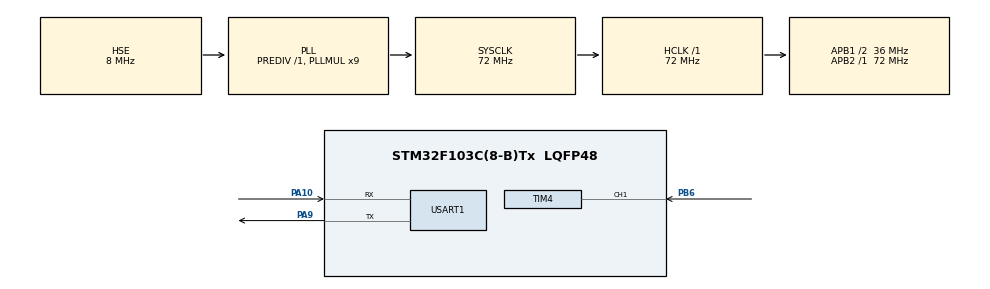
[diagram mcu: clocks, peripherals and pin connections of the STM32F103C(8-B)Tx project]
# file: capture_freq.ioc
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Mcu.Family=STM32F1
Mcu.Name=STM32F103C(8-B)Tx
Mcu.Package=LQFP48
NVIC.PriorityGroup=NVIC_PRIORITYGROUP_4
NVIC.TIM4_IRQn=true\:0\:0\:false\:false\:true\:true\:true
PA10.Mode=Asynchronous
PA10.Signal=USART1_RX
PA13.Mode=Serial_Wire
PA13.Signal=SYS_JTMS-SWDIO
PA14.Mode=Serial_Wire
PA14.Signal=SYS_JTCK-SWCLK
PA9.Mode=Asynchronous
PA9.Signal=USART1_TX
PB6.Signal=S_TIM4_CH1
PD0-OSC_IN.Mode=HSE-External-Oscillator
PD0-OSC_IN.Signal=RCC_OSC_IN
PD1-OSC_OUT.Mode=HSE-External-Oscillator
PD1-OSC_OUT.Signal=RCC_OSC_OUT
ProjectManager.HeapSize=0x200
ProjectManager.StackSize=0x400
ProjectManager.TargetToolchain=TrueSTUDIO
RCC.AHBFreq_Value=72000000
RCC.APB1CLKDivider=RCC_HCLK_DIV2
RCC.APB1Freq_Value=36000000
RCC.APB1TimFreq_Value=72000000
RCC.APB2Freq_Value=72000000
RCC.APB2TimFreq_Value=72000000
RCC.HCLKFreq_Value=72000000
RCC.PLLMUL=RCC_PLL_MUL9
RCC.PLLSourceVirtual=RCC_PLLSOURCE_HSE
RCC.RCC_MCOSource=RCC_MCO1SOURCE_HSE
RCC.SYSCLKFreq_VALUE=72000000
RCC.SYSCLKSource=RCC_SYSCLKSOURCE_PLLCLK
RCC.USBFreq_Value=72000000
SH.S_TIM4_CH1.0=TIM4_CH1,Input_Capture1_from_TI1
TIM3.Period=65535
TIM4.Channel-Input_Capture1_from_TI1=TIM_CHANNEL_1
TIM4.Period=65535
TIM4.Prescaler=71
TIM4.TIM_MasterOutputTrigger=TIM_TRGO_UPDATE
USART1.VirtualMode=VM_ASYNC
VP_TIM3_VS_ClockSourceITR.Mode=TriggerSource_ITR3
VP_TIM3_VS_ControllerModeClock.Mode=Clock Mode
board=custom

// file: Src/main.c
/* USER CODE BEGIN Header */
/**
  ******************************************************************************
  * @file           : main.c
  * @brief          : Main program body
  ******************************************************************************
  * @attention
  *
  * <h2><center>&copy; Copyright (c) 2019 STMicroelectronics.
  * All rights reserved.</center></h2>
  *
  * This software component is licensed by ST under BSD 3-Clause license,
  * the "License"; You may not use this file except in compliance with the
  * License. You may obtain a copy of the License at:
  *                        opensource.org/licenses/BSD-3-Clause
  *
  ******************************************************************************
  */
/* USER CODE END Header */

#include "main.h"

/* USER CODE BEGIN Includes */
#include "string.h"
/* USER CODE END Includes */

TIM_HandleTypeDef htim3;
TIM_HandleTypeDef htim4;

UART_HandleTypeDef huart1;

/* USER CODE BEGIN PV */
volatile uint8_t count = 0;
/* USER CODE END PV */

void SystemClock_Config(void);
static void MX_GPIO_Init(void);
static void MX_TIM4_Init(void);
static void MX_USART1_UART_Init(void);
static void MX_TIM3_Init(void);

/* USER CODE BEGIN 0 */

void HAL_TIM_IC_CaptureCallback(TIM_HandleTypeDef *htim)
{
	if(htim == &htim4)
	{
		if(htim->Channel == HAL_TIM_ACTIVE_CHANNEL_1)
		{
			count++;

			if(count == 1)
			{
				__HAL_TIM_SET_COUNTER(&htim4, 0x0000);
				__HAL_TIM_SET_COUNTER(&htim3, 0x0000);
			}

			else if(count == 2)
			{
				HAL_TIM_IC_Stop_IT(&htim4, TIM_CHANNEL_1);

				count = 0;

				uint16_t count_main = HAL_TIM_ReadCapturedValue(&htim4, TIM_CHANNEL_1);
				uint16_t count_secondary = __HAL_TIM_GET_COUNTER(&htim3);
				uint16_t arr = __HAL_TIM_GET_AUTORELOAD(&htim3);
				uint32_t res = count_main + (count_secondary * arr) + count_secondary;

				float freq = 1 / (res / 1000000.0);

				char str[96] = {0,};
				//snprintf(str, 96, "Capture Freq: %.3f Hz | res: %lu | cm: %d | cs: %d\n", (float)freq, res, count_main, count_secondary);
				snprintf(str, 96, "Capture Freq: %.3f Hz\n", (float)freq);
				HAL_UART_Transmit(&huart1, (uint8_t*)str, strlen(str), 1000);

				HAL_TIM_IC_Start_IT(&htim4, TIM_CHANNEL_1);
			}
		}
	}
}

/* USER CODE END 0 */

int main(void)
{

  /* MCU Configuration--------------------------------------------------------*/

  /* Reset of all peripherals, Initializes the Flash interface and the Systick. */
  HAL_Init();

  /* Configure the system clock */
  SystemClock_Config();

  /* Initialize all configured peripherals */
  MX_GPIO_Init();
  MX_TIM4_Init();
  MX_USART1_UART_Init();
  MX_TIM3_Init();
  /* USER CODE BEGIN 2 */

  HAL_TIM_IC_Start_IT(&htim4, TIM_CHANNEL_1);
  HAL_TIM_Base_Start(&htim3);

  /* USER CODE END 2 */

  /* Infinite loop */
  while (1)
  {

  }
}

void SystemClock_Config(void)
{
  RCC_OscInitTypeDef RCC_OscInitStruct = {0};
  RCC_ClkInitTypeDef RCC_ClkInitStruct = {0};

  /** Initializes the CPU, AHB and APB busses clocks
  */
  RCC_OscInitStruct.OscillatorType = RCC_OSCILLATORTYPE_HSE;
  RCC_OscInitStruct.HSEState = RCC_HSE_ON;
  RCC_OscInitStruct.HSEPredivValue = RCC_HSE_PREDIV_DIV1;
  RCC_OscInitStruct.HSIState = RCC_HSI_ON;
  RCC_OscInitStruct.PLL.PLLState = RCC_PLL_ON;
  RCC_OscInitStruct.PLL.PLLSource = RCC_PLLSOURCE_HSE;
  RCC_OscInitStruct.PLL.PLLMUL = RCC_PLL_MUL9;
  if (HAL_RCC_OscConfig(&RCC_OscInitStruct) != HAL_OK)
  {
    Error_Handler();
  }
  /** Initializes the CPU, AHB and APB busses clocks
  */
  RCC_ClkInitStruct.ClockType = RCC_CLOCKTYPE_HCLK|RCC_CLOCKTYPE_SYSCLK
                              |RCC_CLOCKTYPE_PCLK1|RCC_CLOCKTYPE_PCLK2;
  RCC_ClkInitStruct.SYSCLKSource = RCC_SYSCLKSOURCE_PLLCLK;
  RCC_ClkInitStruct.AHBCLKDivider = RCC_SYSCLK_DIV1;
  RCC_ClkInitStruct.APB1CLKDivider = RCC_HCLK_DIV2;
  RCC_ClkInitStruct.APB2CLKDivider = RCC_HCLK_DIV1;

  if (HAL_RCC_ClockConfig(&RCC_ClkInitStruct, FLASH_LATENCY_2) != HAL_OK)
  {
    Error_Handler();
  }
}

static void MX_TIM3_Init(void)
{

  TIM_SlaveConfigTypeDef sSlaveConfig = {0};
  TIM_MasterConfigTypeDef sMasterConfig = {0};

  htim3.Instance = TIM3;
  htim3.Init.Prescaler = 0;
  htim3.Init.CounterMode = TIM_COUNTERMODE_UP;
  htim3.Init.Period = 65535;
  htim3.Init.ClockDivision = TIM_CLOCKDIVISION_DIV1;
  htim3.Init.AutoReloadPreload = TIM_AUTORELOAD_PRELOAD_DISABLE;
  if (HAL_TIM_Base_Init(&htim3) != HAL_OK)
  {
    Error_Handler();
  }
  sSlaveConfig.SlaveMode = TIM_SLAVEMODE_EXTERNAL1;
  sSlaveConfig.InputTrigger = TIM_TS_ITR3;
  if (HAL_TIM_SlaveConfigSynchronization(&htim3, &sSlaveConfig) != HAL_OK)
  {
    Error_Handler();
  }
  sMasterConfig.MasterOutputTrigger = TIM_TRGO_RESET;
  sMasterConfig.MasterSlaveMode = TIM_MASTERSLAVEMODE_DISABLE;
  if (HAL_TIMEx_MasterConfigSynchronization(&htim3, &sMasterConfig) != HAL_OK)
  {
    Error_Handler();
  }

}

static void MX_TIM4_Init(void)
{

  TIM_MasterConfigTypeDef sMasterConfig = {0};
  TIM_IC_InitTypeDef sConfigIC = {0};

  htim4.Instance = TIM4;
  htim4.Init.Prescaler = 71;
  htim4.Init.CounterMode = TIM_COUNTERMODE_UP;
  htim4.Init.Period = 65535;
  htim4.Init.ClockDivision = TIM_CLOCKDIVISION_DIV1;
  htim4.Init.AutoReloadPreload = TIM_AUTORELOAD_PRELOAD_DISABLE;
  if (HAL_TIM_IC_Init(&htim4) != HAL_OK)
  {
    Error_Handler();
  }
  sMasterConfig.MasterOutputTrigger = TIM_TRGO_UPDATE;
  sMasterConfig.MasterSlaveMode = TIM_MASTERSLAVEMODE_DISABLE;
  if (HAL_TIMEx_MasterConfigSynchronization(&htim4, &sMasterConfig) != HAL_OK)
  {
    Error_Handler();
  }
  sConfigIC.ICPolarity = TIM_INPUTCHANNELPOLARITY_RISING;
  sConfigIC.ICSelection = TIM_ICSELECTION_DIRECTTI;
  sConfigIC.ICPrescaler = TIM_ICPSC_DIV1;
  sConfigIC.ICFilter = 0;
  if (HAL_TIM_IC_ConfigChannel(&htim4, &sConfigIC, TIM_CHANNEL_1) != HAL_OK)
  {
    Error_Handler();
  }

}

static void MX_USART1_UART_Init(void)
{

  huart1.Instance = USART1;
  huart1.Init.BaudRate = 115200;
  huart1.Init.WordLength = UART_WORDLENGTH_8B;
  huart1.Init.StopBits = UART_STOPBITS_1;
  huart1.Init.Parity = UART_PARITY_NONE;
  huart1.Init.Mode = UART_MODE_TX_RX;
  huart1.Init.HwFlowCtl = UART_HWCONTROL_NONE;
  huart1.Init.OverSampling = UART_OVERSAMPLING_16;
  if (HAL_UART_Init(&huart1) != HAL_OK)
  {
    Error_Handler();
  }

}

static void MX_GPIO_Init(void)
{

  /* GPIO Ports Clock Enable */
  __HAL_RCC_GPIOD_CLK_ENABLE();
  __HAL_RCC_GPIOA_CLK_ENABLE();
  __HAL_RCC_GPIOB_CLK_ENABLE();

}

void Error_Handler(void)
{
}

/************************ (C) COPYRIGHT STMicroelectronics *****END OF FILE****/
